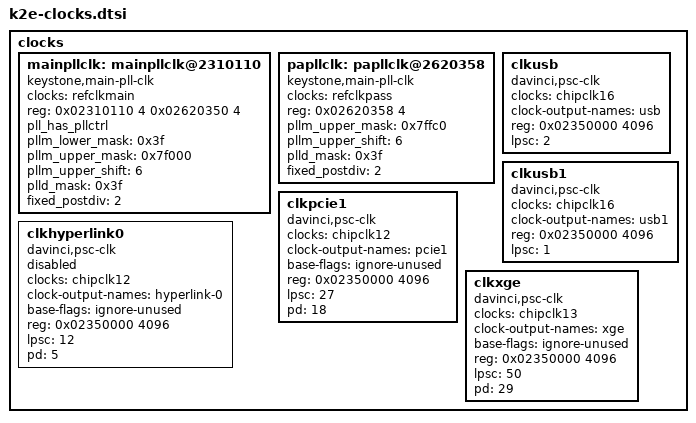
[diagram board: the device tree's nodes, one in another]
/*
 * Copyright 2014 Texas Instruments, Inc.
 *
 * Keystone Edison SoC specific clock driver device bindings
 *
 * This program is free software; you can redistribute it and/or modify
 * it under the terms of the GNU General Public License version 2 as
 * published by the Free Software Foundation.
 */

clocks {
	mainpllclk: mainpllclk@2310110 {
		#clock-cells = <0>;
		compatible = "keystone,main-pll-clk";
		clocks = <&refclkmain>;
		reg = <0x02310110 4	/* PLLCTRL PLLM */
			0x02620350 4>;	/* MAINPLL_CTL0 */
		pll_has_pllctrl;
		pllm_lower_mask	= <0x3f>;
		pllm_upper_mask = <0x7f000>;
		pllm_upper_shift = <6>;
		plld_mask = <0x3f>;
		fixed_postdiv = <2>;
	};

	papllclk: papllclk@2620358 {
		#clock-cells = <0>;
		compatible = "keystone,main-pll-clk";
		clocks = <&refclkpass>;
		reg = <0x02620358 4>;	/* PASSPLLCTL0 */
		pllm_upper_mask = <0x7ffc0>;
		pllm_upper_shift = <6>;
		plld_mask = <0x3f>;
		fixed_postdiv = <2>;
	};

	clkusb: clkusb {
		#clock-cells = <0>;
		compatible = "davinci,psc-clk";
		clocks = <&chipclk16>;
		clock-output-names = "usb";
		reg = <0x02350000 4096>;
		lpsc = <2>;
	};

	clkusb1: clkusb1 {
		#clock-cells = <0>;
		compatible = "davinci,psc-clk";
		clocks = <&chipclk16>;
		clock-output-names = "usb1";
		reg = <0x02350000 4096>;
		lpsc = <1>;
	};

	clkpcie1: clkpcie1 {
		#clock-cells = <0>;
		compatible = "davinci,psc-clk";
		clocks = <&chipclk12>;
		clock-output-names = "pcie1";
		base-flags = "ignore-unused";
		reg = <0x02350000 4096>;
		lpsc = <27>;
		pd = <18>;
	};

	clkhyperlink0: clkhyperlink0 {
		#clock-cells = <0>;
		compatible = "davinci,psc-clk";
		clocks = <&chipclk12>;
		clock-output-names = "hyperlink-0";
		base-flags = "ignore-unused";
		status = "disabled";
		reg = <0x02350000 4096>;
		lpsc = <12>;
		pd = <5>;
	};

	clkxge: clkxge {
		#clock-cells = <0>;
		compatible = "davinci,psc-clk";
		clocks = <&chipclk13>;
		clock-output-names = "xge";
		base-flags = "ignore-unused";
		reg = <0x02350000 4096>;
		lpsc = <50>;
		pd = <29>;
	};
};

